# CMSDK_CM3 register map
Vendor: ARM Ltd.; File version: 1.0
ARM 32-bit Cortex-M3 based device
CPU: CM3 r2p1, little endian, no MPU, no FPU, 0x3 interrupt priority bits, 0x0 interrupts
Registers are 32-bit, read-write, reset 0x0 unless marked. A register's access mark holds for its fields unless they carry their own. Offsets are from the block's base; lines under a group give offsets from that group; [hi:lo] are bit positions; {n}, {i} and the like mark numbered series; 'fields as' and 'values as' point back to an identical list; <NAME> marks a mode.

## Memory map
0x40000000 TIMER0 size 0x10
0x40001000 TIMER1 size 0x10 — Timer 0
0x40002000 DUALTIMER size 0x3C
0x40004000 UART0 size 0x14
0x40005000 UART1 size 0x14 — UART 0
0x40006000 UART2 size 0x14 — UART 0
0x40007000 UART3 size 0x14 — UART 0
0x40008000 WDT size 0xC04 — Watchdog Timer
0x40009000 UART4 size 0x14 — UART 0
0x40010000 GPIO0 size 0x3C — general-purpose I/O
0x40011000 GPIO1 size 0x3C — general-purpose I/O
0x40027000 SPI size 0x40
0x40028000 FPGAIO size 0x100 — FPGA System Control I/O
0x4002F000 SCC size 0x1000 — Serial Communication Controller

## TIMER0
Base 0x40000000
Same registers: TIMER1 0x40001000
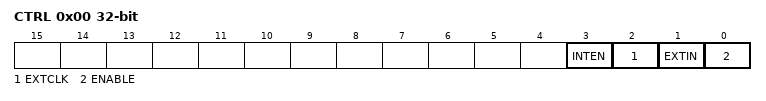
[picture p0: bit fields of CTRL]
0x00 CTRL — Control Register
  [3] INTEN — Interrupt Enable
    0=Disable (Interrupt is disabled); 1=Enable (Interrupt is enabled)
  [2] EXTCLK — External Clock Enable
    0=Disable (External Clock s disabled); 1=Enable (External Clock is enabled)
  [1] EXTIN — External Input as Enable
    0=Disable (External Input as Enable is disabled); 1=Enable (External Input as Enable is enabled)
  [0] ENABLE
    0=Disable (Timer is disabled); 1=Enable (Timer is enabled)
0x04 VALUE — Current Timer Counter Value
0x08 RELOAD — Counter Reload Value
0x0C INTSTATUS ro — Timer Interrupt status register
0x0C INTCLEAR wo write-1-clears — Timer Interrupt clear register

## DUALTIMER
Base 0x40002000
0x00 TIMER1LOAD
0x04 TIMER1VALUE ro reset 0xFFFFFFFF
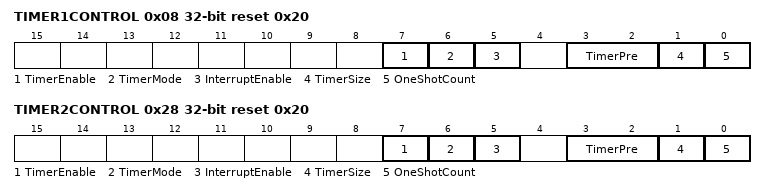
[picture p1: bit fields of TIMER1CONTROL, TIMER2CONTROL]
0x08 TIMER1CONTROL reset 0x20
  [7] TimerEnable — Timer Enable Enable bit.
    0=Disable (Timer is disabled.); 1=Enable (Timer is enabled.)
  [6] TimerMode — Timer Mode bit.
    0=Free-Running timer mode; 1=Periodic timer mode
  [5] InterruptEnable — Interrupt Enable bit.
    0=Disable (Interrupt is disabled.); 1=Enable (Interrupt is enabled.)
  [3:2] TimerPre — Timer prescale bits.
    0=divided by 1 (clock is divided by 1); 1=divided by 16 (clock is divided by 16); 2=divided by 256 (clock is divided by 256)
  [1] TimerSize — Selects 16-bit or 32- bit counter operation.
    0=16-bit counter mode; 1=32-bit counter mode
  [0] OneShotCount — Selects one-shot or wrapping counter mode.
    0=Wrapping counter mode; 1=One-shot counter mode
0x0C TIMER1INTCLR wo — Timer 1 Interrupt Clear Register
  [0] INT write-1-clears — Interrupt
0x10 TIMER1RIS ro — Timer 1 Raw Interrupt Status Register
  [0] RIS — Raw Timer Interrupt
0x14 TIMER1MIS ro — Timer 1 Mask Interrupt Status Register
  [0] MIS — Masked Timer Interrupt
0x18 TIMER1BGLOAD — Timer 1 Background Load Register
0x20 TIMER2LOAD
0x24 TIMER2VALUE ro reset 0xFFFFFFFF
0x28 TIMER2CONTROL reset 0x20
  fields as TIMER1CONTROL
0x2C TIMER2INTCLR wo — Timer 2 Interrupt Clear Register
  [0] INT write-1-clears — Interrupt
0x30 TIMER2RIS ro — Timer 2 Raw Interrupt Status Register
  [0] RIS — Raw Timer Interrupt
0x34 TIMER2MIS ro — Timer 2 Mask Interrupt Status Register
  [0] MIS — Masked Timer Interrupt
0x38 TIMER2BGLOAD — Timer 2 Background Load Register

## UART0
Base 0x40004000
Same registers: UART1 0x40005000, UART2 0x40006000, UART3 0x40007000, UART4 0x40009000
0x00 DATA 8-bit — Recieve and Transmit Data Value
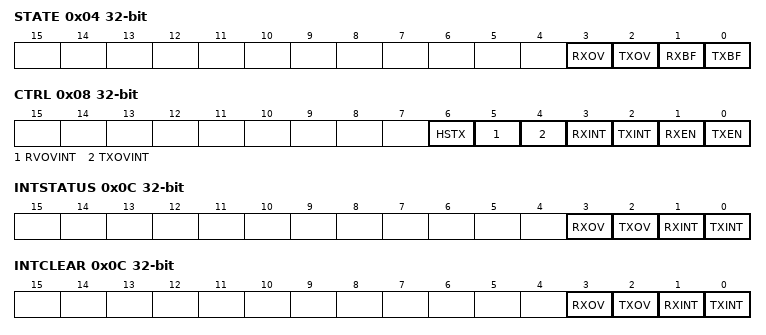
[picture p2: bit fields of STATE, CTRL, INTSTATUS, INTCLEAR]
0x04 STATE — UART Status Register
  [3] RXOV write-1-clears — RX Buffer Overun (write 1 to clear)
  [2] TXOV write-1-clears — TX Buffer Overun (write 1 to clear)
  [1] RXBF ro — RX Buffer Full
  [0] TXBF ro — TX Buffer Full
0x08 CTRL — UART Control Register
  [all] fields
    0=Disabled; 1=Enabled
  [6] HSTX — High Speed Test Mode for TX only
  [5] RVOVINT — RX Overrun Interrupt Enable
  [4] TXOVINT — TX Overrun Interrupt Enable
  [3] RXINT — RX Interrupt Enable
  [2] TXINT — TX Interrupt Enable
  [1] RXEN — RX Enable
  [0] TXEN — TX Enable
0x0C INTSTATUS ro — UART Interrupt Status Register
  [3] RXOV — RX Overrun Interrupt
  [2] TXOV — TX Overrun Interrupt
  [1] RXINT — RX Interrupt
  [0] TXINT — TX Interrupt
0x0C INTCLEAR wo — UART Interrupt CLEAR Register
  [3] RXOV write-1-clears — RX Overrun Interrupt
  [2] TXOV write-1-clears — TX Overrun Interrupt
  [1] RXINT write-1-clears — RX Interrupt
  [0] TXINT write-1-clears — TX Interrupt
0x10 BAUDDIV — Baudrate Divider
